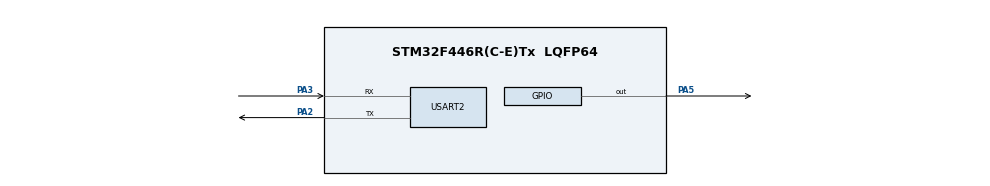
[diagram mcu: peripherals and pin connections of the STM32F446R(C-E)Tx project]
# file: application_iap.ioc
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Mcu.Family=STM32F4
Mcu.Name=STM32F446R(C-E)Tx
Mcu.Package=LQFP64
NVIC.PriorityGroup=NVIC_PRIORITYGROUP_4
PA13.Mode=Serial_Wire
PA13.Signal=SYS_JTMS-SWDIO
PA14.Mode=Serial_Wire
PA14.Signal=SYS_JTCK-SWCLK
PA2.Mode=Asynchronous
PA2.Signal=USART2_TX
PA3.Mode=Asynchronous
PA3.Signal=USART2_RX
PA5.Signal=GPIO_Output
PH0-OSC_IN.Mode=HSE-External-Oscillator
PH0-OSC_IN.Signal=RCC_OSC_IN
PH1-OSC_OUT.Mode=HSE-External-Oscillator
PH1-OSC_OUT.Signal=RCC_OSC_OUT
ProjectManager.HeapSize=0x200
ProjectManager.StackSize=0x400
ProjectManager.TargetToolchain=STM32CubeIDE
RCC.CortexFreq_Value=16000000
RCC.USBFreq_Value=96000000
RCC.VCOOutputFreq_Value=192000000
USART2.VirtualMode=VM_ASYNC
board=custom

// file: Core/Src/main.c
///* USER CODE BEGIN Header */
///**
//  ******************************************************************************
//  * @file           : main.c
//  * @brief          : Main program body
//  ******************************************************************************
//  * @attention
//  *
//  * Copyright (c) 2026 STMicroelectronics.
//  * All rights reserved.
//  *
//  * This software is licensed under terms that can be found in the LICENSE file
//  * in the root directory of this software component.
//  * If no LICENSE file comes with this software, it is provided AS-IS.
//  *
//  ******************************************************************************
//  */
///* USER CODE END Header */
///* Includes ------------------------------------------------------------------*/
//#include "main.h"
//
///* Private includes ----------------------------------------------------------*/
///* USER CODE BEGIN Includes */
//
///* USER CODE END Includes */
//
///* Private typedef -----------------------------------------------------------*/
///* USER CODE BEGIN PTD */
//
///* USER CODE END PTD */
//
///* Private define ------------------------------------------------------------*/
///* USER CODE BEGIN PD */
//#define APP_START_ADDRESS 0x08010000
///* USER CODE END PD */
//
///* Private macro -------------------------------------------------------------*/
///* USER CODE BEGIN PM */
//
///* USER CODE END PM */
//
///* Private variables ---------------------------------------------------------*/
//UART_HandleTypeDef huart2;
//
///* USER CODE BEGIN PV */
//
///* USER CODE END PV */
//
///* Private function prototypes -----------------------------------------------*/
//void SystemClock_Config(void);
//static void MX_GPIO_Init(void);
//static void MX_USART2_UART_Init(void);
///* USER CODE BEGIN PFP */
//
///* USER CODE END PFP */
//
///* Private user code ---------------------------------------------------------*/
///* USER CODE BEGIN 0 */
//
///* USER CODE END 0 */
//
///**
//  * @brief  The application entry point.
//  * @retval int
//  */
//int main(void)
//{
//
//  /* USER CODE BEGIN 1 */
//	  SCB->VTOR = APP_START_ADDRESS;
//
//	  __enable_irq();
//  /* USER CODE END 1 */
//
//  /* MCU Configuration--------------------------------------------------------*/
//
//  /* Reset of all peripherals, Initializes the Flash interface and the Systick. */
//  HAL_Init();
//
//  /* USER CODE BEGIN Init */
//
//  /* USER CODE END Init */
//
//  /* Configure the system clock */
//  SystemClock_Config();
//
//  /* USER CODE BEGIN SysInit */
//
//  /* USER CODE END SysInit */
//
//  /* Initialize all configured peripherals */
//  MX_GPIO_Init();
//  MX_USART2_UART_Init();
//  /* USER CODE BEGIN 2 */
//
//  /* USER CODE END 2 */
//
//  /* Infinite loop */
//  /* USER CODE BEGIN WHILE */
//  while (1)
//  {
//	  HAL_GPIO_TogglePin(GPIOA, GPIO_PIN_5); // Standard Nucleo LED pin
//	  HAL_UART_Transmit(&huart2, (uint8_t*)"APPLICATION", 11, HAL_MAX_DELAY);
//	  HAL_Delay(500);
//    /* USER CODE END WHILE */
//
//    /* USER CODE BEGIN 3 */
//  }
//  /* USER CODE END 3 */
//}
//
///**
//  * @brief System Clock Configuration
//  * @retval None
//  */
//void SystemClock_Config(void)
//{
//  RCC_OscInitTypeDef RCC_OscInitStruct = {0};
//  RCC_ClkInitTypeDef RCC_ClkInitStruct = {0};
//
//  /** Configure the main internal regulator output voltage
//  */
//  __HAL_RCC_PWR_CLK_ENABLE();
//  __HAL_PWR_VOLTAGESCALING_CONFIG(PWR_REGULATOR_VOLTAGE_SCALE3);
//
//  /** Initializes the RCC Oscillators according to the specified parameters
//  * in the RCC_OscInitTypeDef structure.
//  */
//  RCC_OscInitStruct.OscillatorType = RCC_OSCILLATORTYPE_HSI;
//  RCC_OscInitStruct.HSIState = RCC_HSI_ON;
//  RCC_OscInitStruct.HSICalibrationValue = RCC_HSICALIBRATION_DEFAULT;
//  RCC_OscInitStruct.PLL.PLLState = RCC_PLL_NONE;
//  if (HAL_RCC_OscConfig(&RCC_OscInitStruct) != HAL_OK)
//  {
//    Error_Handler();
//  }
//
//  /** Initializes the CPU, AHB and APB buses clocks
//  */
//  RCC_ClkInitStruct.ClockType = RCC_CLOCKTYPE_HCLK|RCC_CLOCKTYPE_SYSCLK
//                              |RCC_CLOCKTYPE_PCLK1|RCC_CLOCKTYPE_PCLK2;
//  RCC_ClkInitStruct.SYSCLKSource = RCC_SYSCLKSOURCE_HSI;
//  RCC_ClkInitStruct.AHBCLKDivider = RCC_SYSCLK_DIV1;
//  RCC_ClkInitStruct.APB1CLKDivider = RCC_HCLK_DIV1;
//  RCC_ClkInitStruct.APB2CLKDivider = RCC_HCLK_DIV1;
//
//  if (HAL_RCC_ClockConfig(&RCC_ClkInitStruct, FLASH_LATENCY_0) != HAL_OK)
//  {
//    Error_Handler();
//  }
//}
//
///**
//  * @brief USART2 Initialization Function
//  * @param None
//  * @retval None
//  */
//static void MX_USART2_UART_Init(void)
//{
//
//  /* USER CODE BEGIN USART2_Init 0 */
//
//  /* USER CODE END USART2_Init 0 */
//
//  /* USER CODE BEGIN USART2_Init 1 */
//
//  /* USER CODE END USART2_Init 1 */
//  huart2.Instance = USART2;
//  huart2.Init.BaudRate = 115200;
//  huart2.Init.WordLength = UART_WORDLENGTH_8B;
//  huart2.Init.StopBits = UART_STOPBITS_1;
//  huart2.Init.Parity = UART_PARITY_NONE;
//  huart2.Init.Mode = UART_MODE_TX_RX;
//  huart2.Init.HwFlowCtl = UART_HWCONTROL_NONE;
//  huart2.Init.OverSampling = UART_OVERSAMPLING_16;
//  if (HAL_UART_Init(&huart2) != HAL_OK)
//  {
//    Error_Handler();
//  }
//  /* USER CODE BEGIN USART2_Init 2 */
//
//  /* USER CODE END USART2_Init 2 */
//
//}
//
///**
//  * @brief GPIO Initialization Function
//  * @param None
//  * @retval None
//  */
//static void MX_GPIO_Init(void)
//{
//  GPIO_InitTypeDef GPIO_InitStruct = {0};
//  /* USER CODE BEGIN MX_GPIO_Init_1 */
//
//  /* USER CODE END MX_GPIO_Init_1 */
//
//  /* GPIO Ports Clock Enable */
//  __HAL_RCC_GPIOH_CLK_ENABLE();
//  __HAL_RCC_GPIOA_CLK_ENABLE();
//
//  /*Configure GPIO pin Output Level */
//  HAL_GPIO_WritePin(GPIOA, GPIO_PIN_5, GPIO_PIN_RESET);
//
//  /*Configure GPIO pin : PA5 */
//  GPIO_InitStruct.Pin = GPIO_PIN_5;
//  GPIO_InitStruct.Mode = GPIO_MODE_OUTPUT_PP;
//  GPIO_InitStruct.Pull = GPIO_NOPULL;
//  GPIO_InitStruct.Speed = GPIO_SPEED_FREQ_LOW;
//  HAL_GPIO_Init(GPIOA, &GPIO_InitStruct);
//
//  /* USER CODE BEGIN MX_GPIO_Init_2 */
//
//  /* USER CODE END MX_GPIO_Init_2 */
//}
//
///* USER CODE BEGIN 4 */
//
///* USER CODE END 4 */
//
///**
//  * @brief  This function is executed in case of error occurrence.
//  * @retval None
//  */
//void Error_Handler(void)
//{
//  /* USER CODE BEGIN Error_Handler_Debug */
//  /* User can add his own implementation to report the HAL error return state */
//  __disable_irq();
//  while (1)
//  {
//  }
//  /* USER CODE END Error_Handler_Debug */
//}
//#ifdef USE_FULL_ASSERT
///**
//  * @brief  Reports the name of the source file and the source line number
//  *         where the assert_param error has occurred.
//  * @param  file: pointer to the source file name
//  * @param  line: assert_param error line source number
//  * @retval None
//  */
//void assert_failed(uint8_t *file, uint32_t line)
//{
//  /* USER CODE BEGIN 6 */
//  /* User can add his own implementation to report the file name and line number,
//     ex: printf("Wrong parameters value: file %s on line %d\r\n", file, line) */
//  /* USER CODE END 6 */
//}
//#endif /* USE_FULL_ASSERT */

/* USER CODE BEGIN Header */
/**
  ******************************************************************************
  * @file           : main.c  (APPLICATION)
  * @brief          : Blinks PA5 LED every 100ms, transmits "APPLICATION" over UART2
  *
  * Memory layout:
  *   - Linked at 0x08010000 (Sector 4) via STM32F446RETX_FLASH.ld
  *   - SCB->VTOR must be set to 0x08010000 before HAL_Init() so all
  *     interrupt vectors resolve to this application's vector table.
  ******************************************************************************
  */
/* USER CODE END Header */

#include "main.h"

/* USER CODE BEGIN PD */
#define APP_START_ADDRESS 0x08008000UL
/* USER CODE END PD */

UART_HandleTypeDef huart2;

void SystemClock_Config(void);
static void MX_GPIO_Init(void);
static void MX_USART2_UART_Init(void);

/**
  * @brief  Application entry point
  */
int main(void)
{
  /* USER CODE BEGIN 1 */
	SCB->VTOR = APP_START_ADDRESS;   // point at the app's vector table, e.g. 0x08008000
;
  __DSB(); // Ensure the write completes before any interrupt can fire
  __enable_irq();
  /* USER CODE END 1 */

  HAL_Init();
  SystemClock_Config();
  MX_GPIO_Init();
  MX_USART2_UART_Init();

  /* Infinite loop */
  while (1)
  {
    HAL_GPIO_TogglePin(GPIOA, GPIO_PIN_5);
    HAL_UART_Transmit(&huart2, (uint8_t*)"APPLICATION\r\n", 13, HAL_MAX_DELAY);
    HAL_Delay(5000);
  }
}

void SystemClock_Config(void)
{
  RCC_OscInitTypeDef RCC_OscInitStruct = {0};
  RCC_ClkInitTypeDef RCC_ClkInitStruct = {0};

  __HAL_RCC_PWR_CLK_ENABLE();
  __HAL_PWR_VOLTAGESCALING_CONFIG(PWR_REGULATOR_VOLTAGE_SCALE3);

  RCC_OscInitStruct.OscillatorType      = RCC_OSCILLATORTYPE_HSI;
  RCC_OscInitStruct.HSIState            = RCC_HSI_ON;
  RCC_OscInitStruct.HSICalibrationValue = RCC_HSICALIBRATION_DEFAULT;
  RCC_OscInitStruct.PLL.PLLState        = RCC_PLL_NONE;
  if (HAL_RCC_OscConfig(&RCC_OscInitStruct) != HAL_OK) Error_Handler();

  RCC_ClkInitStruct.ClockType      = RCC_CLOCKTYPE_HCLK | RCC_CLOCKTYPE_SYSCLK
                                   | RCC_CLOCKTYPE_PCLK1 | RCC_CLOCKTYPE_PCLK2;
  RCC_ClkInitStruct.SYSCLKSource   = RCC_SYSCLKSOURCE_HSI;
  RCC_ClkInitStruct.AHBCLKDivider  = RCC_SYSCLK_DIV1;
  RCC_ClkInitStruct.APB1CLKDivider = RCC_HCLK_DIV1;
  RCC_ClkInitStruct.APB2CLKDivider = RCC_HCLK_DIV1;
  if (HAL_RCC_ClockConfig(&RCC_ClkInitStruct, FLASH_LATENCY_0) != HAL_OK) Error_Handler();
}

/**
  * @brief USART2 Init — 115200 8N1 on PA2(TX)/PA3(RX)
  */
static void MX_USART2_UART_Init(void)
{
  huart2.Instance          = USART2;
  huart2.Init.BaudRate     = 115200;
  huart2.Init.WordLength   = UART_WORDLENGTH_8B;
  huart2.Init.StopBits     = UART_STOPBITS_1;
  huart2.Init.Parity       = UART_PARITY_NONE;
  huart2.Init.Mode         = UART_MODE_TX_RX;
  huart2.Init.HwFlowCtl    = UART_HWCONTROL_NONE;
  huart2.Init.OverSampling = UART_OVERSAMPLING_16;
  if (HAL_UART_Init(&huart2) != HAL_OK) Error_Handler();
}

/**
  * @brief GPIO Init — PA5 as push-pull output (Nucleo LD2 LED)
  */
static void MX_GPIO_Init(void)
{
  GPIO_InitTypeDef GPIO_InitStruct = {0};

  __HAL_RCC_GPIOH_CLK_ENABLE();
  __HAL_RCC_GPIOA_CLK_ENABLE();

  HAL_GPIO_WritePin(GPIOA, GPIO_PIN_5, GPIO_PIN_RESET);

  GPIO_InitStruct.Pin   = GPIO_PIN_5;
  GPIO_InitStruct.Mode  = GPIO_MODE_OUTPUT_PP;
  GPIO_InitStruct.Pull  = GPIO_NOPULL;
  GPIO_InitStruct.Speed = GPIO_SPEED_FREQ_LOW;
  HAL_GPIO_Init(GPIOA, &GPIO_InitStruct);
}

/**
  * @brief Error Handler — disable IRQs and halt
  */
void Error_Handler(void)
{
  __disable_irq();
  while (1) {}
}
